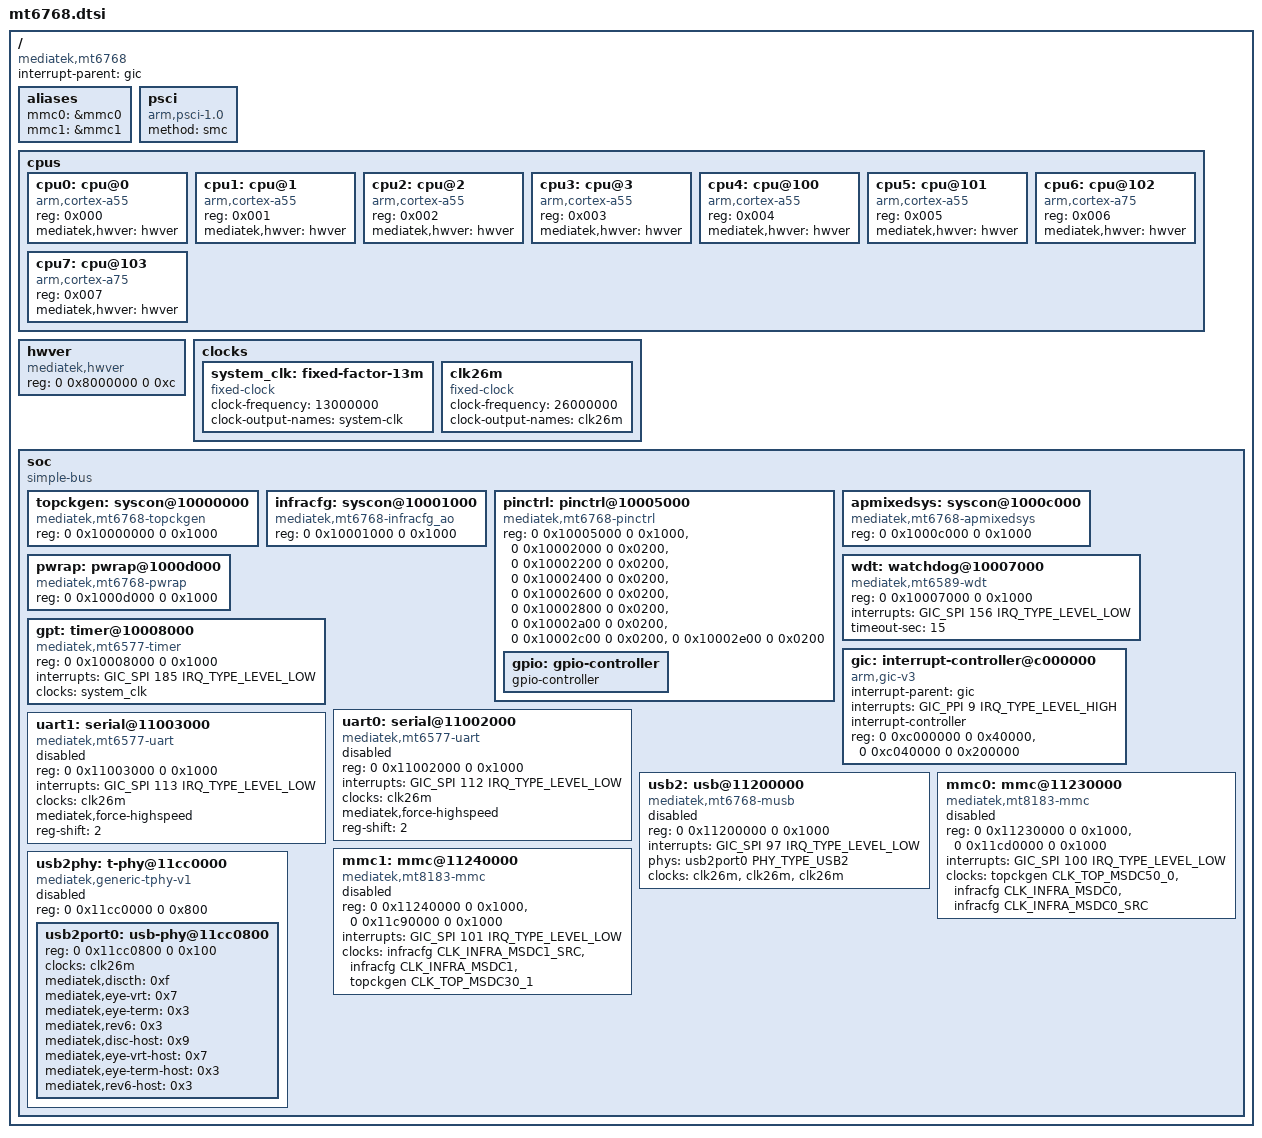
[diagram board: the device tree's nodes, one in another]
#include <dt-bindings/interrupt-controller/irq.h>
#include <dt-bindings/interrupt-controller/arm-gic.h>
#include <dt-bindings/phy/phy.h>
#include <dt-bindings/clock/mediatek,mt6768-clk.h>
#include <dt-bindings/gpio/gpio.h>
#include <dt-bindings/pinctrl/mt65xx.h>

/ {
    compatible = "mediatek,mt6768";
    interrupt-parent = <&gic>;
    #address-cells = <2>;
    #size-cells = <2>;

    aliases {
        mmc0 = &mmc0; // eMMC
        mmc1 = &mmc1; // microSD
    };

    psci {
        compatible = "arm,psci-1.0";
        method = "smc";
    };

    cpus {
        #address-cells = <1>;
        #size-cells = <0>;

        cpu0: cpu@0 {
            device_type = "cpu";
            compatible = "arm,cortex-a55";
            reg = <0x000>;
            mediatek,hwver = <&hwver>;
        };

        cpu1: cpu@1 {
            device_type = "cpu";
            compatible = "arm,cortex-a55";
            reg = <0x001>;
            mediatek,hwver = <&hwver>;
        };

        cpu2: cpu@2 {
            device_type = "cpu";
            compatible = "arm,cortex-a55";
            reg = <0x002>;
            mediatek,hwver = <&hwver>;
        };

        cpu3: cpu@3 {
            device_type = "cpu";
            compatible = "arm,cortex-a55";
            reg = <0x003>;
            mediatek,hwver = <&hwver>;
        };

        cpu4: cpu@100 {
            device_type = "cpu";
            compatible = "arm,cortex-a55";
            reg = <0x004>;
            mediatek,hwver = <&hwver>;
        };

        cpu5: cpu@101 {
            device_type = "cpu";
            compatible = "arm,cortex-a55";
            reg = <0x005>;
            mediatek,hwver = <&hwver>;
        };

        cpu6: cpu@102 {
            device_type = "cpu";
            compatible = "arm,cortex-a75";
            reg = <0x006>;
            mediatek,hwver = <&hwver>;
        };

        cpu7: cpu@103 {
            device_type = "cpu";
            compatible = "arm,cortex-a75";
            reg = <0x007>;
            mediatek,hwver = <&hwver>;
        };
    };

    hwver: hwver {
        compatible = "mediatek,hwver", "syscon";
        reg = <0 0x8000000 0 0xc>;
    };

    clocks {
        system_clk: fixed-factor-13m {
            compatible = "fixed-clock";
            #clock-cells = <0>;
            clock-frequency = <13000000>;
            clock-output-names = "system-clk";
        };

        clk26m: clk26m {
            compatible = "fixed-clock";
            #clock-cells = <0>;
            clock-frequency = <26000000>;
            clock-output-names = "clk26m";
        };
    };

    soc {
        #address-cells = <2>;
        #size-cells = <2>;
        compatible = "simple-bus";
        ranges;

        topckgen: syscon@10000000 {
		compatible = "mediatek,mt6768-topckgen", "syscon";
		reg = <0 0x10000000 0 0x1000>;
		#clock-cells = <1>;
	};

	infracfg: syscon@10001000 {
		compatible = "mediatek,mt6768-infracfg_ao", "syscon";
		reg = <0 0x10001000 0 0x1000>;
		#clock-cells = <1>;
	};

        pinctrl: pinctrl@10005000 {
		compatible = "mediatek,mt6768-pinctrl";
                reg = <0 0x10005000 0 0x1000>,
		      <0 0x10002000 0 0x0200>,
		      <0 0x10002200 0 0x0200>,
		      <0 0x10002400 0 0x0200>,
		      <0 0x10002600 0 0x0200>,
		      <0 0x10002800 0 0x0200>,
		      <0 0x10002a00 0 0x0200>,
		      <0 0x10002c00 0 0x0200>,
		      <0 0x10002e00 0 0x0200>;
		reg-names = "gpio", "iocfg_lt", "iocfg_lm", "iocfg_lb",
			    "iocfg_bl", "iocfg_rm", "iocfg_rb", "iocfg_rt",
			    "iocfg_tl";
		gpio: gpio-controller {
			gpio-controller;
			#gpio-cells = <2>;
		};
	};

	apmixedsys: syscon@1000c000 {
		compatible = "mediatek,mt6768-apmixedsys", "syscon";
		reg = <0 0x1000c000 0 0x1000>;
		#clock-cells = <1>;
	};

        pwrap: pwrap@1000d000 {
            compatible = "mediatek,mt6768-pwrap";
            reg = <0 0x1000d000 0 0x1000>;
        };

        wdt: watchdog@10007000 {
            compatible = "mediatek,mt6589-wdt";
            reg = <0 0x10007000 0 0x1000>;
            interrupts = <GIC_SPI 156 IRQ_TYPE_LEVEL_LOW>;
            timeout-sec = <15>;
            #reset-cells = <1>;
        };

        gpt: timer@10008000 {
            compatible = "mediatek,mt6577-timer";
            reg = <0 0x10008000 0 0x1000>;
            interrupts = <GIC_SPI 185 IRQ_TYPE_LEVEL_LOW>;
            clocks = <&system_clk>;
            clock-names = "system-clk";
        };

        gic: interrupt-controller@c000000 {
            compatible = "arm,gic-v3";
            #interrupt-cells = <3>;
            interrupt-parent = <&gic>;
            interrupts = <GIC_PPI 9 IRQ_TYPE_LEVEL_HIGH>;
            interrupt-controller;
            reg =   <0 0xc000000 0 0x40000>,
                    <0 0xc040000 0 0x200000>;
        };

        uart0: serial@11002000 {
            compatible = "mediatek,mt6577-uart";
            reg = <0 0x11002000 0 0x1000>;
            interrupts = <GIC_SPI 112 IRQ_TYPE_LEVEL_LOW>;
            clocks = <&clk26m>;
            clock-names = "clk26m";
            mediatek,force-highspeed;
            reg-shift = <2>;
            status = "disabled";
        };

        uart1: serial@11003000 {
            compatible = "mediatek,mt6577-uart";
            reg = <0 0x11003000 0 0x1000>;
            interrupts = <GIC_SPI 113 IRQ_TYPE_LEVEL_LOW>;
            clocks = <&clk26m>;
            clock-names = "clk26m";
            mediatek,force-highspeed;
            reg-shift = <2>;
            status = "disabled";
        };

        usb2: usb@11200000 {
            compatible = "mediatek,mt6768-musb";
            reg = <0 0x11200000 0 0x1000>;
            reg-names = "control";
            interrupts = <GIC_SPI 97 IRQ_TYPE_LEVEL_LOW>;
            interrupt-names = "mc";
            phys = <&usb2port0 PHY_TYPE_USB2>;
            phy-names = "usb";
            clocks = <&clk26m>, <&clk26m>, <&clk26m>;
            clock-names = "usbpll", "usbmcu", "usb";
            status = "disabled";
        };

    	mmc0: mmc@11230000 {
	    compatible = "mediatek,mt8183-mmc";
	    reg = <0 0x11230000 0 0x1000>,
	          <0 0x11cd0000 0 0x1000>;
	    interrupts = <GIC_SPI 100 IRQ_TYPE_LEVEL_LOW>;
	    clocks = <&topckgen CLK_TOP_MSDC50_0>,
	    	 <&infracfg CLK_INFRA_MSDC0>,
	    	 <&infracfg CLK_INFRA_MSDC0_SRC>;
	    clock-names = "source", "hclk", "source_cg";
	    status = "disabled";
	};

    	mmc1: mmc@11240000 {
	    compatible = "mediatek,mt8183-mmc";
	    reg = <0 0x11240000 0 0x1000>,
	          <0 0x11c90000 0 0x1000>;
	    interrupts = <GIC_SPI 101 IRQ_TYPE_LEVEL_LOW>;
	    clocks = <&infracfg CLK_INFRA_MSDC1_SRC>,
	    	 <&infracfg CLK_INFRA_MSDC1>,
	    	 <&topckgen CLK_TOP_MSDC30_1>;
	    clock-names = "source", "hclk", "source_cg";
	    status = "disabled";
	};

        usb2phy: t-phy@11cc0000 {
            compatible = "mediatek,generic-tphy-v1";
            reg = <0 0x11cc0000 0 0x800>;
            #address-cells = <2>;
            #size-cells = <2>;
            ranges;
            status = "disabled";

            usb2port0: usb-phy@11cc0800 {
                reg = <0 0x11cc0800 0 0x100>;
                clocks = <&clk26m>;
                clock-names = "ref";
            	mediatek,discth = <0xf>;
		mediatek,eye-vrt = <0x7>;
		mediatek,eye-term = <0x3>;
		mediatek,rev6 = <0x3>;
		mediatek,disc-host= <0x9>;
		mediatek,eye-vrt-host = <0x7>;
		mediatek,eye-term-host = <0x3>;
		mediatek,rev6-host = <0x3>;
                #phy-cells = <1>;
            };
        };
    };
};
